# V850 register map
Vendor: Renesas; Series: E1/E2/CA2; File version: 1.2
CPU: V850 r1, little endian, no MPU, no FPU, 3 interrupt priority bits
Registers are 8-bit, read-write, reset 0x0 unless marked. A register's access mark holds for its fields unless they carry their own. Offsets are from the block's base; [hi:lo] are bit positions; 'fields as' and 'values as' point back to an identical list.

## MEMORY — SRAM, External ROM, External I/O Interface
Base 0xFFFFF49A
0xFFFFF49A PRC reset 0x7000 (reset mask 0x7000) — Page ROM Configuration Register
  [0] MA3 — Controls the internal count clock

## Interrupt/Exception_Processing — The V850E/CA2 is provided with a dedicated interrupt controller (INTC) for interrupt servicing and can process a total of 64 maskable and three non-maskable interrupt requests. An interrupt is an event that occurs independently of program execution, and an exception is an event whose occurrence is dependent on program execution. Generally, an exception takes precedence over an interrupt. The V850E/CA2 can process interrupt requests from the on-chip peripheral hardware and external sources. Moreover, exception processing can be started by the TRAP instruction (software exception) or by generation of an exception event (i.e. fetching of an illegal opcode) (exception trap). Eight levels of software-programmable priorities can be specified for each interrupt request. Interrupt servicing starts after no fewer than 11 system clocks (343 ns (@ 32 MHz)) following the generation of an interrupt request.
Base 0x00000000
0xFFFFF886 INTM3 — Edge Detection Function
  [0] ESNO — Specifies the NMI pin's valid edge
    0=falling (NMI on falling edge); 1=rising (NMI on rising edge)

## TIMERC — 16 bit Timer / Counter
Base 0xFFFFF600
Same registers: TIMERD 0xFFFFF540, TIMERG 0xFFFFF648
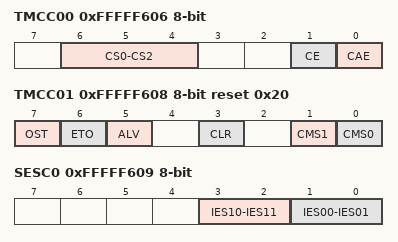
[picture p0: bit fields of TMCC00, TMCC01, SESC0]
0xFFFFF606 TMCC00 — Control Register for Timer C
  [6:4] CS0-CS2 — Selects the internal count clock for TMC0.
    0=fPCLK/2; 1=fPCLK/4; 2=fPCLK/8; 3=fPCLK/16; 4=fPCLK/32; 5=fPCLK/64; 6=fPCLK/128; 7=fPCLK/256
  [1] CE — Controls the operation of TMC0
    0=Disable count (timer stopped at 0000H and does not operate); 1=enable (Perform count operation.)
  [0] CAE — Controls the internal count clock
    0=reset (Asynchronously reset entire TMC0 unit. Stop base clock supply to TMC0 unit.); 1=init (Supply peripheral-clock (fPCLK) to TMC0 unit.)
0xFFFFF608 TMCC01 reset 0x20 — Control Register for Timer C
  [7] OST — Setting of the timer operation after overflow
    0=overflow-continue (After overflow the count operation is continued (free running mode)); 1=overflow-stop (After overflow the count operation is stopped (overflow stop mode). The count is restarted by writing "1" to the CE bit.)
  [6] ETO — ETO: Enables/disables output of external pulse output (TOC0)
    0=Disable external pulse output. Output of inactive level of ALV bit to TOC0 pin is fixed. TOC0 pin level remains unchanged even if match signal from corresponding compare register is generated.; 1=Enable external pulse output. Compare register match causes TOC0 output to change. However, in capture mode, TOC0 output does not change. An ALV bit inactive level is output from the time when timer output is enabled until a match signal is generated.
  [5] ALV — Specifies active level of external pulse output (TOC0).
    0=low-level (Active level is low level.); 1=high-level (Active level is high level.)
  [3] CLR — Enables/disables TMC0 clearing during compare operation.
    0=Disable clearing; 1=Enable clearing (TMC0 is cleared when CCC00 and TMC0 match during com- pare operation)
  [1] CMS1 — Selects operation mode of capture/compare register (CCC01)
    0=capture (Register operates as capture register.); 1=compare (Register operates as compare register.)
  [0] CMS0 — Selects operation mode of capture/compare register (CCC00)
    values as CMS1
0xFFFFF609 SESC0 — Valid edge selection register (SESC0)
  [3:2] IES10-IES11 — Specifies the valid edge of TIC10 pins.
    0=Falling edge; 1=Rising edge; 2=prohibited (Setting prohibited); 3=Both rising and falling edges
  [1:0] IES00-IES01 — Specifies the valid edge of TIC00 pins.
    values as IES10-IES11
